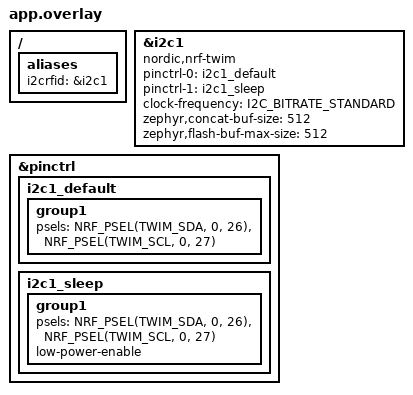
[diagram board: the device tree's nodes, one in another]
/ {
    aliases {
        i2crfid = &i2c1;
    };
};

&i2c1 {
    status = "okay";
    compatible = "nordic,nrf-twim";

    pinctrl-0 = <&i2c1_default>;
    pinctrl-1 = <&i2c1_sleep>;
    pinctrl-names = "default", "sleep";
    clock-frequency = <I2C_BITRATE_STANDARD>;
    
    zephyr,concat-buf-size = <512>;
    zephyr,flash-buf-max-size = <512>;
};

&pinctrl {
    i2c1_default: i2c1_default {
        group1 {
            psels = <NRF_PSEL(TWIM_SDA, 0, 26)>,
                    <NRF_PSEL(TWIM_SCL, 0, 27)>;
        };
    };

    i2c1_sleep: i2c1_sleep {
        group1 {
            psels = <NRF_PSEL(TWIM_SDA, 0, 26)>,
                    <NRF_PSEL(TWIM_SCL, 0, 27)>;
            low-power-enable;
        };
    };
};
